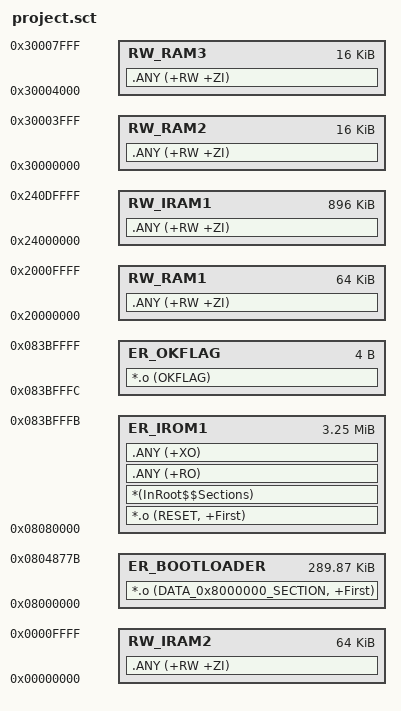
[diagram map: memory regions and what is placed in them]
; *************************************************************
; *** Scatter-Loading Description File generated by uVision ***
; *************************************************************

LR_IROM1 0x08080000 0x033FFFC  {    ; load region size_region
  ER_IROM1 0x08080000 0x033FFFC  {  ; load address = execution address
   *.o (RESET, +First)
   *(InRoot$$Sections)
   .ANY (+RO)
   .ANY (+XO)
  }
  RW_RAM1 0x20000000 0x00010000  {  ; RW data
   .ANY (+RW +ZI)
  }
  RW_RAM2 0x30000000 0x00004000  {
   .ANY (+RW +ZI)
  }
  RW_RAM3 0x30004000 0x00004000  {
   .ANY (+RW +ZI)
  }
  RW_IRAM1 0x24000000 0x000E0000  {
   .ANY (+RW +ZI)
  }
  RW_IRAM2 0x00000000 0x00010000  {
   .ANY (+RW +ZI)
  }
}

LR_OKFLAG  0x083BFFFC  0x4  {
   ER_OKFLAG 0x083BFFFC 0x4 {
    *.o (OKFLAG)
  }
}
LR_BOOTLOADER  0x8000000  0x4877c  {
  ER_BOOTLOADER  0x8000000  0x4877c  {
    *.o (DATA_0x8000000_SECTION, +First)
  }
}
